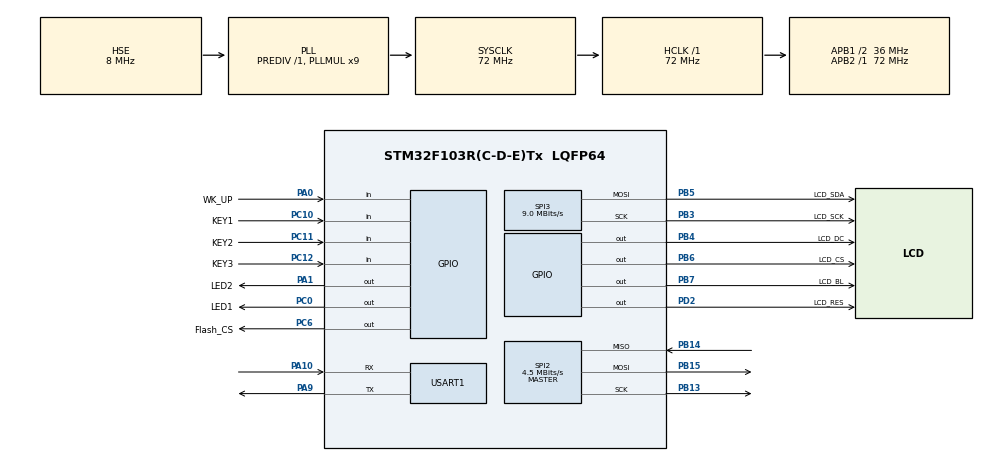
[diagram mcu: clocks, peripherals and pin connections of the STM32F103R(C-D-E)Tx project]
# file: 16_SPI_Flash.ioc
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Mcu.Family=STM32F1
Mcu.Name=STM32F103R(C-D-E)Tx
Mcu.Package=LQFP64
NVIC.PriorityGroup=NVIC_PRIORITYGROUP_2
NVIC.TIM6_IRQn=true\:1\:0\:true\:false\:true\:true\:true\:true
NVIC.TIM7_IRQn=true\:1\:1\:true\:false\:true\:true\:true\:true
PA0-WKUP.GPIO_Label=WK_UP
PA0-WKUP.GPIO_PuPd=GPIO_PULLDOWN
PA0-WKUP.Signal=GPIO_Input
PA1.GPIO_Label=LED2
PA1.PinState=GPIO_PIN_SET
PA1.Signal=GPIO_Output
PA10.Mode=Asynchronous
PA10.Signal=USART1_RX
PA13.Mode=Serial_Wire
PA13.Signal=SYS_JTMS-SWDIO
PA14.Mode=Serial_Wire
PA14.Signal=SYS_JTCK-SWCLK
PA9.Mode=Asynchronous
PA9.Signal=USART1_TX
PB13.Mode=Full_Duplex_Master
PB13.Signal=SPI2_SCK
PB14.Mode=Full_Duplex_Master
PB14.Signal=SPI2_MISO
PB15.Mode=Full_Duplex_Master
PB15.Signal=SPI2_MOSI
PB3.GPIO_Label=LCD_SCK
PB3.Mode=TX_Only_Simplex_Unidirect_Master
PB3.Signal=SPI3_SCK
PB4.GPIO_Label=LCD_DC
PB4.GPIO_Speed=GPIO_SPEED_FREQ_HIGH
PB4.PinState=GPIO_PIN_SET
PB4.Signal=GPIO_Output
PB5.GPIO_Label=LCD_SDA
PB5.Mode=TX_Only_Simplex_Unidirect_Master
PB5.Signal=SPI3_MOSI
PB6.GPIO_Label=LCD_CS
PB6.GPIO_Speed=GPIO_SPEED_FREQ_HIGH
PB6.PinState=GPIO_PIN_SET
PB6.Signal=GPIO_Output
PB7.GPIO_Label=LCD_BL
PB7.GPIO_PuPd=GPIO_NOPULL
PB7.PinState=GPIO_PIN_RESET
PB7.Signal=GPIO_Output
PC0.GPIO_Label=LED1
PC0.PinState=GPIO_PIN_SET
PC0.Signal=GPIO_Output
PC10.GPIO_Label=KEY1
PC10.GPIO_PuPd=GPIO_PULLUP
PC10.Signal=GPIO_Input
PC11.GPIO_Label=KEY2
PC11.GPIO_PuPd=GPIO_PULLUP
PC11.Signal=GPIO_Input
PC12.GPIO_Label=KEY3
PC12.GPIO_PuPd=GPIO_PULLUP
PC12.Signal=GPIO_Input
PC14-OSC32_IN.Mode=LSE-External-Oscillator
PC14-OSC32_IN.Signal=RCC_OSC32_IN
PC15-OSC32_OUT.Mode=LSE-External-Oscillator
PC15-OSC32_OUT.Signal=RCC_OSC32_OUT
PC6.GPIO_Label=Flash_CS
PC6.PinState=GPIO_PIN_SET
PC6.Signal=GPIO_Output
PD0-OSC_IN.Mode=HSE-External-Oscillator
PD0-OSC_IN.Signal=RCC_OSC_IN
PD1-OSC_OUT.Mode=HSE-External-Oscillator
PD1-OSC_OUT.Signal=RCC_OSC_OUT
PD2.GPIO_Label=LCD_RES
PD2.Signal=GPIO_Output
ProjectManager.HeapSize=0x200
ProjectManager.StackSize=0x400
ProjectManager.TargetToolchain=CMake
RCC.AHBFreq_Value=72000000
RCC.APB1CLKDivider=RCC_HCLK_DIV2
RCC.APB1Freq_Value=36000000
RCC.APB1TimFreq_Value=72000000
RCC.APB2Freq_Value=72000000
RCC.APB2TimFreq_Value=72000000
RCC.HCLKFreq_Value=72000000
RCC.PLLMUL=RCC_PLL_MUL9
RCC.PLLSourceVirtual=RCC_PLLSOURCE_HSE
RCC.SYSCLKFreq_VALUE=72000000
RCC.SYSCLKSource=RCC_SYSCLKSOURCE_PLLCLK
RCC.USBFreq_Value=72000000
SPI2.BaudRatePrescaler=SPI_BAUDRATEPRESCALER_8
SPI2.CLKPhase=SPI_PHASE_2EDGE
SPI2.CLKPolarity=SPI_POLARITY_HIGH
SPI2.CRCCalculation=SPI_CRCCALCULATION_DISABLE
SPI2.CalculateBaudRate=4.5 MBits/s
SPI2.Direction=SPI_DIRECTION_2LINES
SPI2.Mode=SPI_MODE_MASTER
SPI2.VirtualType=VM_MASTER
SPI3.BaudRatePrescaler=SPI_BAUDRATEPRESCALER_4
SPI3.CalculateBaudRate=9.0 MBits/s
SPI3.Direction=SPI_DIRECTION_2LINES
SPI3.Mode=SPI_MODE_MASTER
SPI3.VirtualType=VM_MASTER
TIM6.Period=9
TIM6.Prescaler=7199
TIM7.Period=4999
TIM7.Prescaler=7199
USART1.VirtualMode=VM_ASYNC
VP_TIM6_VS_ClockSourceINT.Mode=Enable_Timer
VP_TIM7_VS_ClockSourceINT.Mode=Enable_Timer
board=custom

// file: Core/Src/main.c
/* USER CODE BEGIN Header */
/**
  ******************************************************************************
  * @file           : main.c
  * @brief          : Main program body
  ******************************************************************************
  * @attention
  *
  * Copyright (c) 2025 STMicroelectronics.
  * All rights reserved.
  *
  * This software is licensed under terms that can be found in the LICENSE file
  * in the root directory of this software component.
  * If no LICENSE file comes with this software, it is provided AS-IS.
  *
  ******************************************************************************
  */
/* USER CODE END Header */
#include "main.h"
#include "spi.h"
#include "tim.h"
#include "usart.h"
#include "gpio.h"

/* USER CODE BEGIN Includes */
#include "app.h"
#include "retarget.h"
/* USER CODE END Includes */

void SystemClock_Config(void);

int main(void)
{

  /* MCU Configuration--------------------------------------------------------*/

  /* Reset of all peripherals, Initializes the Flash interface and the Systick. */
  HAL_Init();

  /* Configure the system clock */
  SystemClock_Config();

  /* Initialize all configured peripherals */
  MX_GPIO_Init();
  MX_USART1_UART_Init();
  MX_SPI3_Init();
  MX_SPI2_Init();
  MX_TIM6_Init();
  MX_TIM7_Init();
  /* USER CODE BEGIN 2 */
    RetargetInit(&huart1);
    app_main();
  /* USER CODE END 2 */

  /* Infinite loop */
  while (1)
  {

  }
}

void SystemClock_Config(void)
{
  RCC_OscInitTypeDef RCC_OscInitStruct = {0};
  RCC_ClkInitTypeDef RCC_ClkInitStruct = {0};

  /** Initializes the RCC Oscillators according to the specified parameters
  * in the RCC_OscInitTypeDef structure.
  */
  RCC_OscInitStruct.OscillatorType = RCC_OSCILLATORTYPE_HSE;
  RCC_OscInitStruct.HSEState = RCC_HSE_ON;
  RCC_OscInitStruct.HSEPredivValue = RCC_HSE_PREDIV_DIV1;
  RCC_OscInitStruct.HSIState = RCC_HSI_ON;
  RCC_OscInitStruct.PLL.PLLState = RCC_PLL_ON;
  RCC_OscInitStruct.PLL.PLLSource = RCC_PLLSOURCE_HSE;
  RCC_OscInitStruct.PLL.PLLMUL = RCC_PLL_MUL9;
  if (HAL_RCC_OscConfig(&RCC_OscInitStruct) != HAL_OK)
  {
    Error_Handler();
  }

  /** Initializes the CPU, AHB and APB buses clocks
  */
  RCC_ClkInitStruct.ClockType = RCC_CLOCKTYPE_HCLK|RCC_CLOCKTYPE_SYSCLK
                              |RCC_CLOCKTYPE_PCLK1|RCC_CLOCKTYPE_PCLK2;
  RCC_ClkInitStruct.SYSCLKSource = RCC_SYSCLKSOURCE_PLLCLK;
  RCC_ClkInitStruct.AHBCLKDivider = RCC_SYSCLK_DIV1;
  RCC_ClkInitStruct.APB1CLKDivider = RCC_HCLK_DIV2;
  RCC_ClkInitStruct.APB2CLKDivider = RCC_HCLK_DIV1;

  if (HAL_RCC_ClockConfig(&RCC_ClkInitStruct, FLASH_LATENCY_2) != HAL_OK)
  {
    Error_Handler();
  }
}

void Error_Handler(void)
{
  __disable_irq();
  while (1)
  {
  }
}
